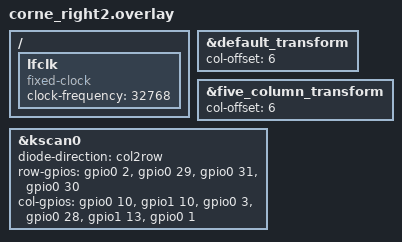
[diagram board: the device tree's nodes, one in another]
/*
 * Copyright (c) 2020 Pete Johanson
 *
 * SPDX-License-Identifier: MIT
 */

#include "corne.dtsi"

&default_transform {
    col-offset = <6>;
};

&five_column_transform {
    col-offset = <6>;
};


&kscan0 {
    diode-direction = "col2row";
    row-gpios
        = <&gpio0  2 (GPIO_ACTIVE_HIGH | GPIO_PULL_DOWN)>
        , <&gpio0  29 (GPIO_ACTIVE_HIGH | GPIO_PULL_DOWN)>
        , <&gpio0  31 (GPIO_ACTIVE_HIGH | GPIO_PULL_DOWN)>
        , <&gpio0 30 (GPIO_ACTIVE_HIGH | GPIO_PULL_DOWN)>
        ;

    col-gpios
        = <&gpio0 10 GPIO_ACTIVE_HIGH>
        , <&gpio1 10 GPIO_ACTIVE_HIGH>
        , <&gpio0 3 GPIO_ACTIVE_HIGH>
        , <&gpio0 28 GPIO_ACTIVE_HIGH>
        , <&gpio1 13 GPIO_ACTIVE_HIGH>
        , <&gpio0 1 GPIO_ACTIVE_HIGH>
        ;
};


/ {
    lfclk: lfclk {
        compatible = "fixed-clock";
        clock-frequency = <32768>;
        #clock-cells = <0>;
        status = "okay";
    };
};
